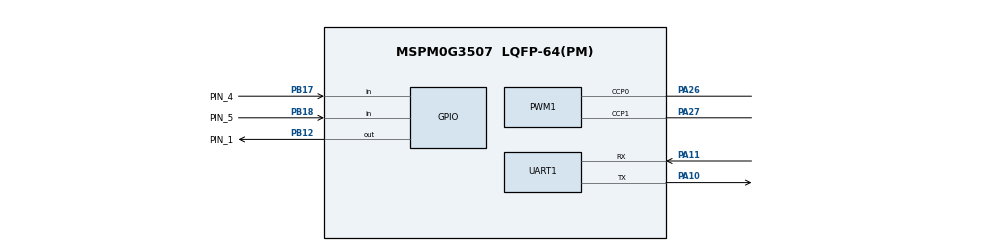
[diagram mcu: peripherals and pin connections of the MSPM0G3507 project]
/**
 * These arguments were used when this file was generated. They will be automatically applied on subsequent loads
 * via the GUI or CLI. Run CLI with '--help' for additional information on how to override these arguments.
 * @cliArgs --device "MSPM0G350X" --part "Default" --package "LQFP-64(PM)" --product "mspm0_sdk@2.05.01.01"
 * @v2CliArgs --device "MSPM0G3507" --package "LQFP-64(PM)" --product "mspm0_sdk@2.05.01.01"
 * @versions {"tool":"1.24.0+4110"}
 */

/**
 * Import the modules used in this configuration.
 */
const GPIO          = scripting.addModule("/ti/driverlib/GPIO", {}, false);
const GPIO1         = GPIO.addInstance();
const GPIO2         = GPIO.addInstance();
const GPIO3         = GPIO.addInstance();
const I2C           = scripting.addModule("/ti/driverlib/I2C", {}, false);
const I2C1          = I2C.addInstance();
const I2C2          = I2C.addInstance();
const MATHACL       = scripting.addModule("/ti/driverlib/MATHACL");
const PWM           = scripting.addModule("/ti/driverlib/PWM", {}, false);
const PWM1          = PWM.addInstance();
const SYSCTL        = scripting.addModule("/ti/driverlib/SYSCTL");
const TIMER         = scripting.addModule("/ti/driverlib/TIMER", {}, false);
const TIMER1        = TIMER.addInstance();
const UART          = scripting.addModule("/ti/driverlib/UART", {}, false);
const UART1         = UART.addInstance();
const ProjectConfig = scripting.addModule("/ti/project_config/ProjectConfig");

/**
 * Write custom configuration values to the imported modules.
 */
const gate7  = system.clockTree["MFCLKGATE"];
gate7.enable = true;

GPIO1.$name                          = "motorA";
GPIO1.associatedPins.create(2);
GPIO1.associatedPins[0].$name        = "PIN_0";
GPIO1.associatedPins[1].$name        = "PIN_1";
GPIO1.associatedPins[1].initialValue = "SET";
GPIO1.associatedPins[1].pin.$assign  = "PB12";

const Board = scripting.addModule("/ti/driverlib/Board", {}, false);

GPIO2.$name                   = "motorB";
GPIO2.associatedPins.create(2);
GPIO2.associatedPins[0].$name = "PIN_2";
GPIO2.associatedPins[1].$name = "PIN_3";

GPIO3.$name                         = "ENCODERL";
GPIO3.associatedPins.create(2);
GPIO3.associatedPins[0].$name       = "PIN_4";
GPIO3.associatedPins[0].direction   = "INPUT";
GPIO3.associatedPins[0].ioStructure = "SD";
GPIO3.associatedPins[0].interruptEn = true;
GPIO3.associatedPins[0].polarity    = "RISE";
GPIO3.associatedPins[0].pin.$assign = "PB17";
GPIO3.associatedPins[1].$name       = "PIN_5";
GPIO3.associatedPins[1].direction   = "INPUT";
GPIO3.associatedPins[1].ioStructure = "SD";
GPIO3.associatedPins[1].pin.$assign = "PB18";

I2C1.$name                           = "I2C_0";
I2C1.basicEnableController           = true;
I2C1.basicControllerStandardBusSpeed = "Fast";
I2C1.peripheral.$assign              = "I2C0";
I2C1.sdaPinConfig.$name              = "ti_driverlib_gpio_GPIOPinGeneric0";
I2C1.sclPinConfig.$name              = "ti_driverlib_gpio_GPIOPinGeneric1";

I2C2.$name                             = "I2C_TRACE";
I2C2.sdaPinConfig.hideOutputInversion  = scripting.forceWrite(false);
I2C2.sdaPinConfig.onlyInternalResistor = scripting.forceWrite(false);
I2C2.sdaPinConfig.passedPeripheralType = scripting.forceWrite("Digital");
I2C2.sdaPinConfig.$name                = "ti_driverlib_gpio_GPIOPinGeneric6";
I2C2.sclPinConfig.hideOutputInversion  = scripting.forceWrite(false);
I2C2.sclPinConfig.onlyInternalResistor = scripting.forceWrite(false);
I2C2.sclPinConfig.passedPeripheralType = scripting.forceWrite("Digital");
I2C2.sclPinConfig.$name                = "ti_driverlib_gpio_GPIOPinGeneric7";

PWM1.$name                              = "PWM_MOTOR";
PWM1.clockDivider                       = 8;
PWM1.timerStartTimer                    = true;
PWM1.pwmMode                            = "EDGE_ALIGN_UP";
PWM1.peripheral.$assign                 = "TIMG8";
PWM1.peripheral.ccp0Pin.$assign         = "PA26";
PWM1.peripheral.ccp1Pin.$assign         = "PA27";
PWM1.PWM_CHANNEL_0.$name                = "ti_driverlib_pwm_PWMTimerCC0";
PWM1.PWM_CHANNEL_0.dutyCycle            = 50;
PWM1.PWM_CHANNEL_1.$name                = "ti_driverlib_pwm_PWMTimerCC1";
PWM1.ccp0PinConfig.$name                = "ti_driverlib_gpio_GPIOPinGeneric4";
PWM1.ccp0PinConfig.direction            = scripting.forceWrite("OUTPUT");
PWM1.ccp0PinConfig.hideOutputInversion  = scripting.forceWrite(false);
PWM1.ccp0PinConfig.onlyInternalResistor = scripting.forceWrite(false);
PWM1.ccp0PinConfig.passedPeripheralType = scripting.forceWrite("Digital");
PWM1.ccp1PinConfig.$name                = "ti_driverlib_gpio_GPIOPinGeneric5";
PWM1.ccp1PinConfig.direction            = scripting.forceWrite("OUTPUT");
PWM1.ccp1PinConfig.hideOutputInversion  = scripting.forceWrite(false);
PWM1.ccp1PinConfig.onlyInternalResistor = scripting.forceWrite(false);
PWM1.ccp1PinConfig.passedPeripheralType = scripting.forceWrite("Digital");

SYSCTL.forceDefaultClkConfig = true;
SYSCTL.clockTreeEn           = true;

TIMER1.$name              = "TIMER_0";
TIMER1.timerClkDiv        = 8;
TIMER1.timerClkPrescale   = 100;
TIMER1.timerStartTimer    = true;
TIMER1.interrupts         = ["ZERO"];
TIMER1.timerMode          = "PERIODIC";
TIMER1.timerPeriod        = "50 ms";
TIMER1.peripheral.$assign = "TIMG0";

UART1.$name                    = "UART_0";
UART1.enabledInterrupts        = ["RX"];
UART1.uartClkSrc               = "MFCLK";
UART1.peripheral.rxPin.$assign = "PA11";
UART1.peripheral.txPin.$assign = "PA10";
UART1.txPinConfig.$name        = "ti_driverlib_gpio_GPIOPinGeneric2";
UART1.rxPinConfig.$name        = "ti_driverlib_gpio_GPIOPinGeneric3";

ProjectConfig.genLibIQ    = true;
ProjectConfig.genLibCMSIS = true;

/**
 * Pinmux solution for unlocked pins/peripherals. This ensures that minor changes to the automatic solver in a future
 * version of the tool will not impact the pinmux you originally saw.  These lines can be completely deleted in order to
 * re-solve from scratch.
 */
GPIO1.associatedPins[0].pin.$suggestSolution = "PB13";
Board.peripheral.$suggestSolution            = "DEBUGSS";
Board.peripheral.swclkPin.$suggestSolution   = "PA20";
Board.peripheral.swdioPin.$suggestSolution   = "PA19";
GPIO2.associatedPins[0].pin.$suggestSolution = "PB14";
GPIO2.associatedPins[1].pin.$suggestSolution = "PB15";
I2C1.peripheral.sdaPin.$suggestSolution      = "PA0";
I2C1.peripheral.sclPin.$suggestSolution      = "PA1";
I2C2.peripheral.$suggestSolution             = "I2C1";
I2C2.peripheral.sdaPin.$suggestSolution      = "PA16";
I2C2.peripheral.sclPin.$suggestSolution      = "PA15";
UART1.peripheral.$suggestSolution            = "UART0";
